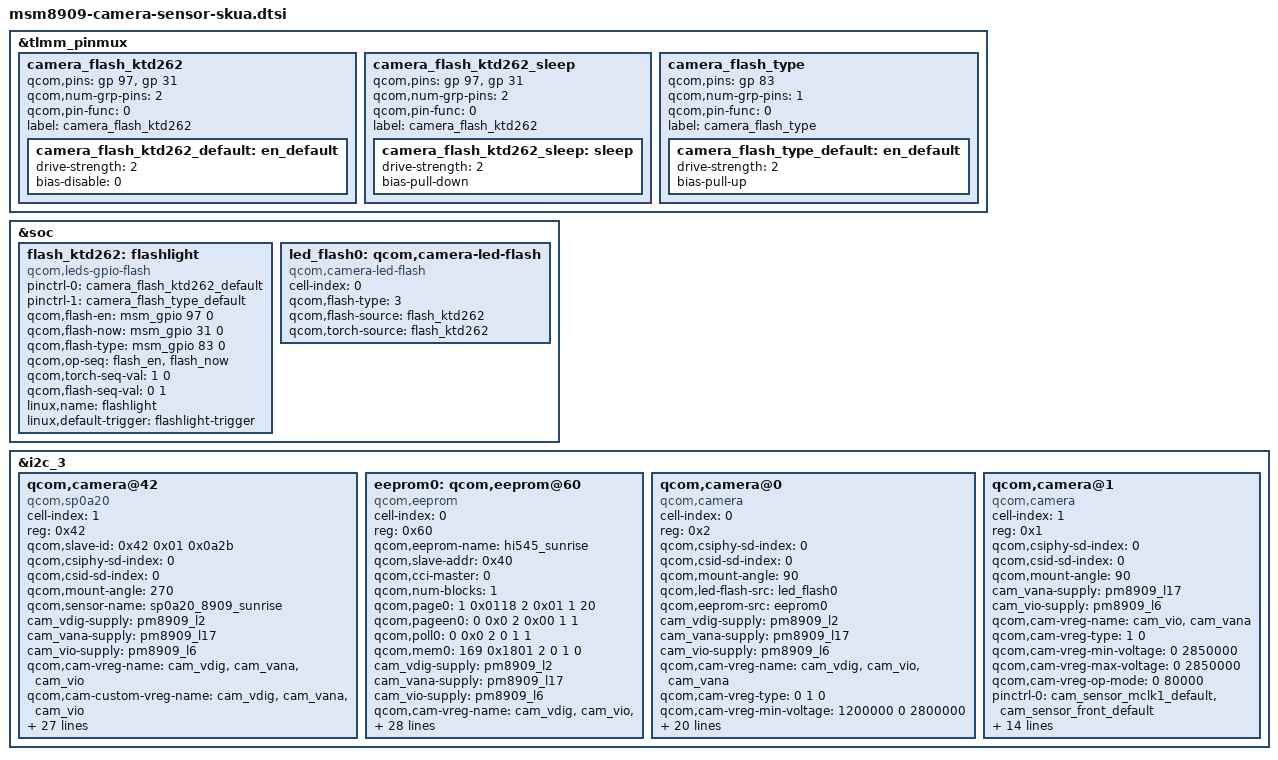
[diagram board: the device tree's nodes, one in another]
/*
 * Copyright (c) 2014, The Linux Foundation. All rights reserved.
 *
 * This program is free software; you can redistribute it and/or modify
 * it under the terms of the GNU General Public License version 2 and
 * only version 2 as published by the Free Software Foundation.
 *
 * This program is distributed in the hope that it will be useful,
 * but WITHOUT ANY WARRANTY; without even the implied warranty of
 * MERCHANTABILITY or FITNESS FOR A PARTICULAR PURPOSE.  See the
 * GNU General Public License for more details.
 */

&tlmm_pinmux {
	camera_flash_ktd262 {
		qcom,pins = <&gp 97>, <&gp 31>;
		qcom,num-grp-pins = <2>;
		qcom,pin-func = <0>;
		label = "camera_flash_ktd262";
		camera_flash_ktd262_default: en_default {
			  drive-strength = <2>;
			  bias-disable = <0>;
		};
	};
	
	camera_flash_ktd262_sleep {
		/* FLSH_RESET,FLASH_EN,FLASH_NOW */
		qcom,pins = <&gp 97>,<&gp 31> ;
		qcom,num-grp-pins = <2>;
		qcom,pin-func = <0>;
		label = "camera_flash_ktd262";
		/* active state */
		camera_flash_ktd262_sleep: sleep {
			drive-strength = <2>; /* 2 MA */
			bias-pull-down; /* PULL DOWN */
		};
	};	

	camera_flash_type{
		qcom,pins = <&gp 83>;
		qcom,num-grp-pins = <1>;
		qcom,pin-func = <0>;
		label = "camera_flash_type";
		camera_flash_type_default: en_default {
			drive-strength = <2>; /* 2 MA */
			bias-pull-up; /* PULL DOWN */
		};
	};
};

&soc {
	flash_ktd262:flashlight {
		compatible = "qcom,leds-gpio-flash";
		status = "okay";
		pinctrl-names = "camera_flash_ktd262_default", "camera_flash_type_default";
		pinctrl-0 = <&camera_flash_ktd262_default>;
		pinctrl-1 = <&camera_flash_type_default>;
		qcom,flash-en = <&msm_gpio 97 0>;
		qcom,flash-now = <&msm_gpio 31 0>;
		qcom,flash-type = <&msm_gpio 83 0>;
		qcom,op-seq = "flash_en", "flash_now";
		qcom,torch-seq-val = <1 0>;
		qcom,flash-seq-val = <0 1>;
		linux,name = "flashlight";
		linux,default-trigger = "flashlight-trigger";
	};

	led_flash0: qcom,camera-led-flash {
		cell-index = <0>;
		compatible = "qcom,camera-led-flash";
		qcom,flash-type = <3>;
		qcom,flash-source = <&flash_ktd262>;
		qcom,torch-source = <&flash_ktd262>;
	};
};

&i2c_3 {

	qcom,camera@42 {
		cell-index = <1>;
		compatible = "qcom,sp0a20";
		reg = <0x42 >;
		qcom,slave-id = <0x42 0x01 0x0a2b>;
		qcom,csiphy-sd-index = <0>;
		qcom,csid-sd-index = <0>;
		qcom,mount-angle = <270>;
		qcom,sensor-name = "sp0a20_8909_sunrise";
		cam_vdig-supply = <&pm8909_l2>;
		cam_vana-supply = <&pm8909_l17>;
		cam_vio-supply = <&pm8909_l6>;
		qcom,cam-vreg-name = "cam_vdig","cam_vana","cam_vio";
		qcom,cam-custom-vreg-name = "cam_vdig","cam_vana","cam_vio";
		qcom,cam-vreg-type = <0 0 0>;
		qcom,cam-vreg-min-voltage = <1200000 2800000 1800000>;
		qcom,cam-vreg-max-voltage = <1200000 2850000 1800000>;
		qcom,cam-vreg-op-mode = <0 80000 0>;
		qcom,enable_pinctrl;
		pinctrl-names = "cam_default", "cam_suspend";
		pinctrl-0 = <&cam_sensor_mclk1_default
				&cam_sensor_front_default>;
		pinctrl-1 = <&cam_sensor_mclk1_sleep &cam_sensor_front_sleep>;
		gpios = <&msm_gpio 27 0>,
			<&msm_gpio 28 0>,
			<&msm_gpio 33 0>,
			<&msm_gpio 11 0>;
		qcom,gpio-reset = <1>;
		qcom,gpio-standby = <2>;
		qcom,gpio-vana = <3>;
		qcom,gpio-req-tbl-num = <0 1 2 3>;
		qcom,gpio-req-tbl-flags = <1 0 0 0>;
		qcom,gpio-req-tbl-label = "CAMIF_MCLK1",
					"CAM_RESET1",
					"CAM_STANDBY1",
					"CAM_VANA";
		qcom,csi-lane-assign = <0x4320>;
		qcom,csi-lane-mask = <0x3>;
		qcom,sensor-position = <1>;
		qcom,sensor-mode = <0>;
		qcom,cci-master = <0>;
		clocks = <&clock_gcc clk_mclk1_clk_src>,
				<&clock_gcc clk_gcc_camss_mclk1_clk>;
		clock-names = "cam_src_clk", "cam_clk";
		status = "ok";
	};
	
	eeprom0: qcom,eeprom@60 {
	   cell-index = <0>;
	   reg = <0x60>;
	   qcom,eeprom-name = "hi545_sunrise";
	   compatible = "qcom,eeprom";
	   qcom,slave-addr = <0x40>;
	   qcom,cci-master = <0>;
	   qcom,num-blocks = <1>;



	   qcom,page0 = <1 0x0118 2 0x01 1 20>;//sensor  sleep read regs
	   qcom,pageen0 = <0 0x0 2 0x00 1 1>;
	   qcom,poll0 = <0 0x0 2 0 1 1>;
	   qcom,mem0 = <169 0x1801 2 0 1 0>;

	   cam_vdig-supply = <&pm8909_l2>;
	   cam_vana-supply = <&pm8909_l17>;
	   cam_vio-supply = <&pm8909_l6>;
	   qcom,cam-vreg-name = "cam_vdig", "cam_vio", "cam_vana";
	   qcom,cam-vreg-type = <0 1 0>;
	   qcom,cam-vreg-min-voltage = <1200000 0 2800000>;
	   qcom,cam-vreg-max-voltage = <1200000 0 2850000>;
	   qcom,cam-vreg-op-mode = <200000 0 80000>;
		
	   pinctrl-names = "cam_default", "cam_suspend";

	   pinctrl-0 = <&cam_sensor_mclk0_default
			   &cam_sensor_rear_default>;
	   pinctrl-1 = <&cam_sensor_mclk0_sleep &cam_sensor_rear_sleep>;

	   gpios = <&msm_gpio 26 0>,
		   <&msm_gpio 35 0>,
		   <&msm_gpio 34 0>,
		   <&msm_gpio 11 0>;
	   qcom,gpio-reset = <1>;
	   qcom,gpio-standby = <2>;
	   qcom,gpio-vana = <3>;
	   qcom,gpio-req-tbl-num = <0 1 2 3>;
	   qcom,gpio-req-tbl-flags = <1 0 0 0>;
	   qcom,gpio-req-tbl-label = "CAMIF_MCLK",
		   "CAM_RESET1",
		   "CAM_STANDBY",
		   "CAM_VANA";

	   qcom,cam-power-seq-type = "sensor_vreg","sensor_vreg","sensor_gpio",
		   "sensor_gpio", "sensor_gpio" ,"sensor_clk";
		   
	   qcom,cam-power-seq-val = "cam_vio","cam_vana","sensor_gpio_vana",
		   "sensor_gpio_reset", "sensor_gpio_standby","sensor_cam_mclk";
	   qcom,cam-power-seq-cfg-val = <1 1 1 1 1 23880000>;
	   qcom,cam-power-seq-delay = <5 5 5 5 5 5>;

	   
	   clocks = <&clock_gcc clk_mclk0_clk_src>,
			   <&clock_gcc clk_gcc_camss_mclk0_clk>;
	   clock-names = "cam_src_clk", "cam_clk";
			
	};
	
	qcom,camera@0 {
		cell-index = <0>;
		compatible = "qcom,camera";
		reg = <0x2>;
		qcom,csiphy-sd-index = <0>;
		qcom,csid-sd-index = <0>;
		qcom,mount-angle = <90>;
		qcom,led-flash-src = <&led_flash0>;
		qcom,eeprom-src = <&eeprom0>;
		cam_vdig-supply = <&pm8909_l2>;
		cam_vana-supply = <&pm8909_l17>;
		cam_vio-supply = <&pm8909_l6>;
		qcom,cam-vreg-name = "cam_vdig", "cam_vio", "cam_vana";
		qcom,cam-vreg-type = <0 1 0>;
		qcom,cam-vreg-min-voltage = <1200000 0 2800000>;
		qcom,cam-vreg-max-voltage = <1200000 0 2850000>;
		qcom,cam-vreg-op-mode = <200000 0 80000>;
		pinctrl-names = "cam_default", "cam_suspend";
		pinctrl-0 = <&cam_sensor_mclk0_default
				&cam_sensor_rear_default>;
		pinctrl-1 = <&cam_sensor_mclk0_sleep &cam_sensor_rear_sleep>;
		gpios = <&msm_gpio 26 0>,
			<&msm_gpio 35 0>,
			<&msm_gpio 34 0>,
			<&msm_gpio 11 0>;
		qcom,gpio-reset = <1>;
		qcom,gpio-standby = <2>;
		qcom,gpio-vana = <3>;
		qcom,gpio-req-tbl-num = <0 1 2 3>;
		qcom,gpio-req-tbl-flags = <1 0 0 0>;
		qcom,gpio-req-tbl-label = "CAMIF_MCLK",
			"CAM_RESET1",
			"CAM_STANDBY",
			"CAM_VANA";
		qcom,sensor-position = <0>;
		qcom,sensor-mode = <0>;
		qcom,cci-master = <0>;
		status = "ok";
		clocks = <&clock_gcc clk_mclk0_clk_src>,
				<&clock_gcc clk_gcc_camss_mclk0_clk>;
		clock-names = "cam_src_clk", "cam_clk";
	};

	qcom,camera@1 {
		cell-index = <1>;
		compatible = "qcom,camera";
		reg = <0x1>;
		qcom,csiphy-sd-index = <0>;
		qcom,csid-sd-index = <0>;
		qcom,mount-angle = <90>;
		cam_vana-supply = <&pm8909_l17>;
		cam_vio-supply = <&pm8909_l6>;
		qcom,cam-vreg-name = "cam_vio", "cam_vana";
		qcom,cam-vreg-type = <1 0>;
		qcom,cam-vreg-min-voltage = <0 2850000>;
		qcom,cam-vreg-max-voltage = <0 2850000>;
		qcom,cam-vreg-op-mode = <0 80000>;
		pinctrl-names = "cam_default", "cam_suspend";
		pinctrl-0 = <&cam_sensor_mclk1_default &cam_sensor_front_default>;
		pinctrl-1 = <&cam_sensor_mclk1_sleep &cam_sensor_front_sleep>;
		gpios = <&msm_gpio 27 0>,
			<&msm_gpio 28 0>,
			<&msm_gpio 33 0>,
			<&msm_gpio 11 0>;
		qcom,gpio-reset = <1>;
		qcom,gpio-standby = <2>;
		qcom,gpio-vana = <3>;
		qcom,gpio-req-tbl-num = <0 1 2 3>;
		qcom,gpio-req-tbl-flags = <1 0 0 0>;
		qcom,gpio-req-tbl-label = "CAMIF_MCLK",
			"CAM_RESET",
			"CAM_STANDBY",
			"CAM_VANA";
		qcom,cci-master = <0>;
		status = "ok";
		clocks = <&clock_gcc clk_mclk1_clk_src>,
				<&clock_gcc clk_gcc_camss_mclk1_clk>;
		clock-names = "cam_src_clk", "cam_clk";
	};

};
